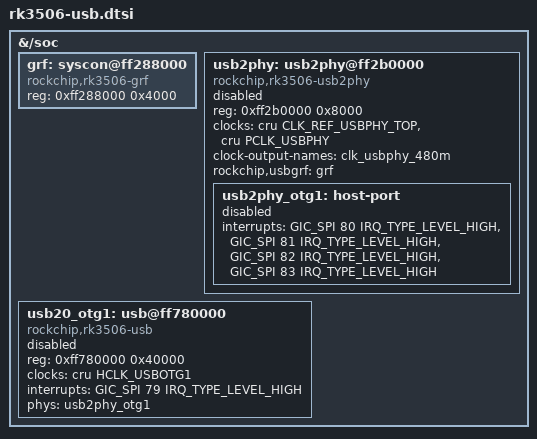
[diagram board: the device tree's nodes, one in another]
// SPDX-License-Identifier: (GPL-2.0+ OR MIT)
/*
 * RK3506 OTG1. Register and interrupt assignments from the Rockchip TRM
 * and the RK3506 device tree by Jonas Karlman (linux-rockchip 7e4c7f871924).
 */

#include <dt-bindings/clock/rockchip,rk3506-cru.h>
#include <dt-bindings/interrupt-controller/arm-gic.h>

&{/soc} {
	grf: syscon@ff288000 {
		compatible = "rockchip,rk3506-grf", "syscon", "simple-mfd";
		reg = <0xff288000 0x4000>;
	};

	usb2phy: usb2phy@ff2b0000 {
		compatible = "rockchip,rk3506-usb2phy";
		reg = <0xff2b0000 0x8000>;
		clocks = <&cru CLK_REF_USBPHY_TOP>, <&cru PCLK_USBPHY>;
		clock-names = "phyclk", "pclk";
		#clock-cells = <0>;
		clock-output-names = "clk_usbphy_480m";
		rockchip,usbgrf = <&grf>;
		status = "disabled";

		usb2phy_otg1: host-port {
			#phy-cells = <0>;
			interrupts = <GIC_SPI 80 IRQ_TYPE_LEVEL_HIGH>,
				     <GIC_SPI 81 IRQ_TYPE_LEVEL_HIGH>,
				     <GIC_SPI 82 IRQ_TYPE_LEVEL_HIGH>,
				     <GIC_SPI 83 IRQ_TYPE_LEVEL_HIGH>;
			interrupt-names = "otg-bvalid", "otg-id", "linestate",
					  "disconnect";
			status = "disabled";
		};
	};

	usb20_otg1: usb@ff780000 {
		compatible = "rockchip,rk3506-usb", "rockchip,rk3066-usb",
			     "snps,dwc2";
		reg = <0xff780000 0x40000>;
		clocks = <&cru HCLK_USBOTG1>;
		clock-names = "otg";
		interrupts = <GIC_SPI 79 IRQ_TYPE_LEVEL_HIGH>;
		phys = <&usb2phy_otg1>;
		phy-names = "usb2-phy";
		status = "disabled";
	};
};
